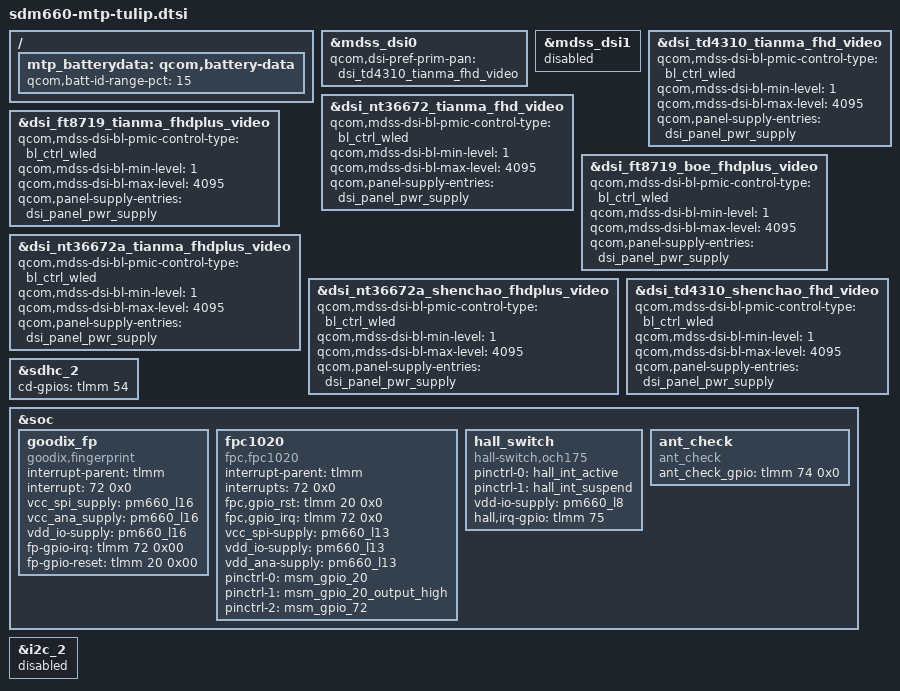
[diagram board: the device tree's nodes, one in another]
/* Copyright (c) 2016-2017, The Linux Foundation. All rights reserved.
 * Copyright (C) 2018 XiaoMi, Inc.
 *
 * This program is free software; you can redistribute it and/or modify
 * it under the terms of the GNU General Public License version 2 and
 * only version 2 as published by the Free Software Foundation.
 *
 * This program is distributed in the hope that it will be useful,
 * but WITHOUT ANY WARRANTY; without even the implied warranty of
 * MERCHANTABILITY or FITNESS FOR A PARTICULAR PURPOSE.  See the
 * GNU General Public License for more details.
 */

/ {
	/delete-node/qcom,battery-data;
	mtp_batterydata: qcom,battery-data {
		qcom,batt-id-range-pct = <15>;
		#include "../common/battery/fg-gen3-batterydata-l6660cos-4000mah.dtsi"
		#include "../common/battery/fg-gen3-batterydata-l6660desay-4000mah.dtsi"
		#include "../common/battery/fg-gen3-batterydata-l6660atl-4000mah.dtsi"
	};
};

&mdss_dsi0 {
	qcom,dsi-pref-prim-pan = <&dsi_td4310_tianma_fhd_video>;
};

&mdss_dsi1 {
	status = "disabled";
};

&dsi_td4310_tianma_fhd_video {
	qcom,mdss-dsi-bl-pmic-control-type = "bl_ctrl_wled";
	qcom,mdss-dsi-bl-min-level = <1>;
	qcom,mdss-dsi-bl-max-level = <4095>;
	qcom,panel-supply-entries = <&dsi_panel_pwr_supply>;
};

&dsi_nt36672_tianma_fhd_video {
	qcom,mdss-dsi-bl-pmic-control-type = "bl_ctrl_wled";
	qcom,mdss-dsi-bl-min-level = <1>;
	qcom,mdss-dsi-bl-max-level = <4095>;
	qcom,panel-supply-entries = <&dsi_panel_pwr_supply>;
};
&dsi_ft8719_tianma_fhdplus_video {
	qcom,mdss-dsi-bl-pmic-control-type = "bl_ctrl_wled";
	qcom,mdss-dsi-bl-min-level = <1>;
	qcom,mdss-dsi-bl-max-level = <4095>;
	qcom,panel-supply-entries = <&dsi_panel_pwr_supply>;
};

&dsi_ft8719_boe_fhdplus_video {
        qcom,mdss-dsi-bl-pmic-control-type = "bl_ctrl_wled";
        qcom,mdss-dsi-bl-min-level = <1>;
        qcom,mdss-dsi-bl-max-level = <4095>;
        qcom,panel-supply-entries = <&dsi_panel_pwr_supply>;
};

&dsi_nt36672a_tianma_fhdplus_video {
	qcom,mdss-dsi-bl-pmic-control-type = "bl_ctrl_wled";
	qcom,mdss-dsi-bl-min-level = <1>;
	qcom,mdss-dsi-bl-max-level = <4095>;
	qcom,panel-supply-entries = <&dsi_panel_pwr_supply>;
};

&dsi_nt36672a_shenchao_fhdplus_video {
        qcom,mdss-dsi-bl-pmic-control-type = "bl_ctrl_wled";
        qcom,mdss-dsi-bl-min-level = <1>;
        qcom,mdss-dsi-bl-max-level = <4095>;
        qcom,panel-supply-entries = <&dsi_panel_pwr_supply>;
};

&dsi_td4310_shenchao_fhd_video {
	qcom,mdss-dsi-bl-pmic-control-type = "bl_ctrl_wled";
	qcom,mdss-dsi-bl-min-level = <1>;
	qcom,mdss-dsi-bl-max-level = <4095>;
	qcom,panel-supply-entries = <&dsi_panel_pwr_supply>;
};

&sdhc_2 {
	cd-gpios = <&tlmm 54 0x0>;
};

&soc {
	goodix_fp {
	compatible = "goodix,fingerprint";
	interrupt-parent = <&tlmm>;
	interrupt = <72 0x0>;
        vcc_spi_supply = <&pm660_l16>;
	vcc_ana_supply = <&pm660_l16>;
	vdd_io-supply = <&pm660_l16>;
	fp-gpio-irq = <&tlmm 72 0x00>;
	fp-gpio-reset = <&tlmm 20 0x00>;
	status = "okay";
	};

	fpc1020 {
		status = "ok";
		compatible = "fpc,fpc1020";
		interrupt-parent = <&tlmm>;
		interrupts = <72 0x0>;
		fpc,gpio_rst    = <&tlmm 20 0x0>;
		fpc,gpio_irq    = <&tlmm 72 0x0>;
		vcc_spi-supply  = <&pm660_l13>;
		vdd_io-supply   = <&pm660_l13>;
		vdd_ana-supply  = <&pm660_l13>;

		pinctrl-names = "fpc1020_reset_reset",
			"fpc1020_reset_active",
			"fpc1020_irq_active";

		pinctrl-0 = <&msm_gpio_20>;
		pinctrl-1 = <&msm_gpio_20_output_high>;
		pinctrl-2 = <&msm_gpio_72>;
	};
	hall_switch {

		compatible = "hall-switch,och175";
		pinctrl-names = "hall_active","hall_suspend";
		pinctrl-0 = <&hall_int_active>;
		pinctrl-1 = <&hall_int_suspend>;
		//interrupt-parent = <&msm_gpio>;
		//interrupts = <0 107 3>;
		vdd-io-supply= <&pm660_l8>;
		interrupt-names = "hall_irq";
	        hall,irq-gpio = <&tlmm 75 0x0>;
	};
	ant_check {
		compatible = "ant_check";
	        ant_check_gpio = <&tlmm 74 0x0>;
	};
};

&i2c_2 {
	status = "disabled";
};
